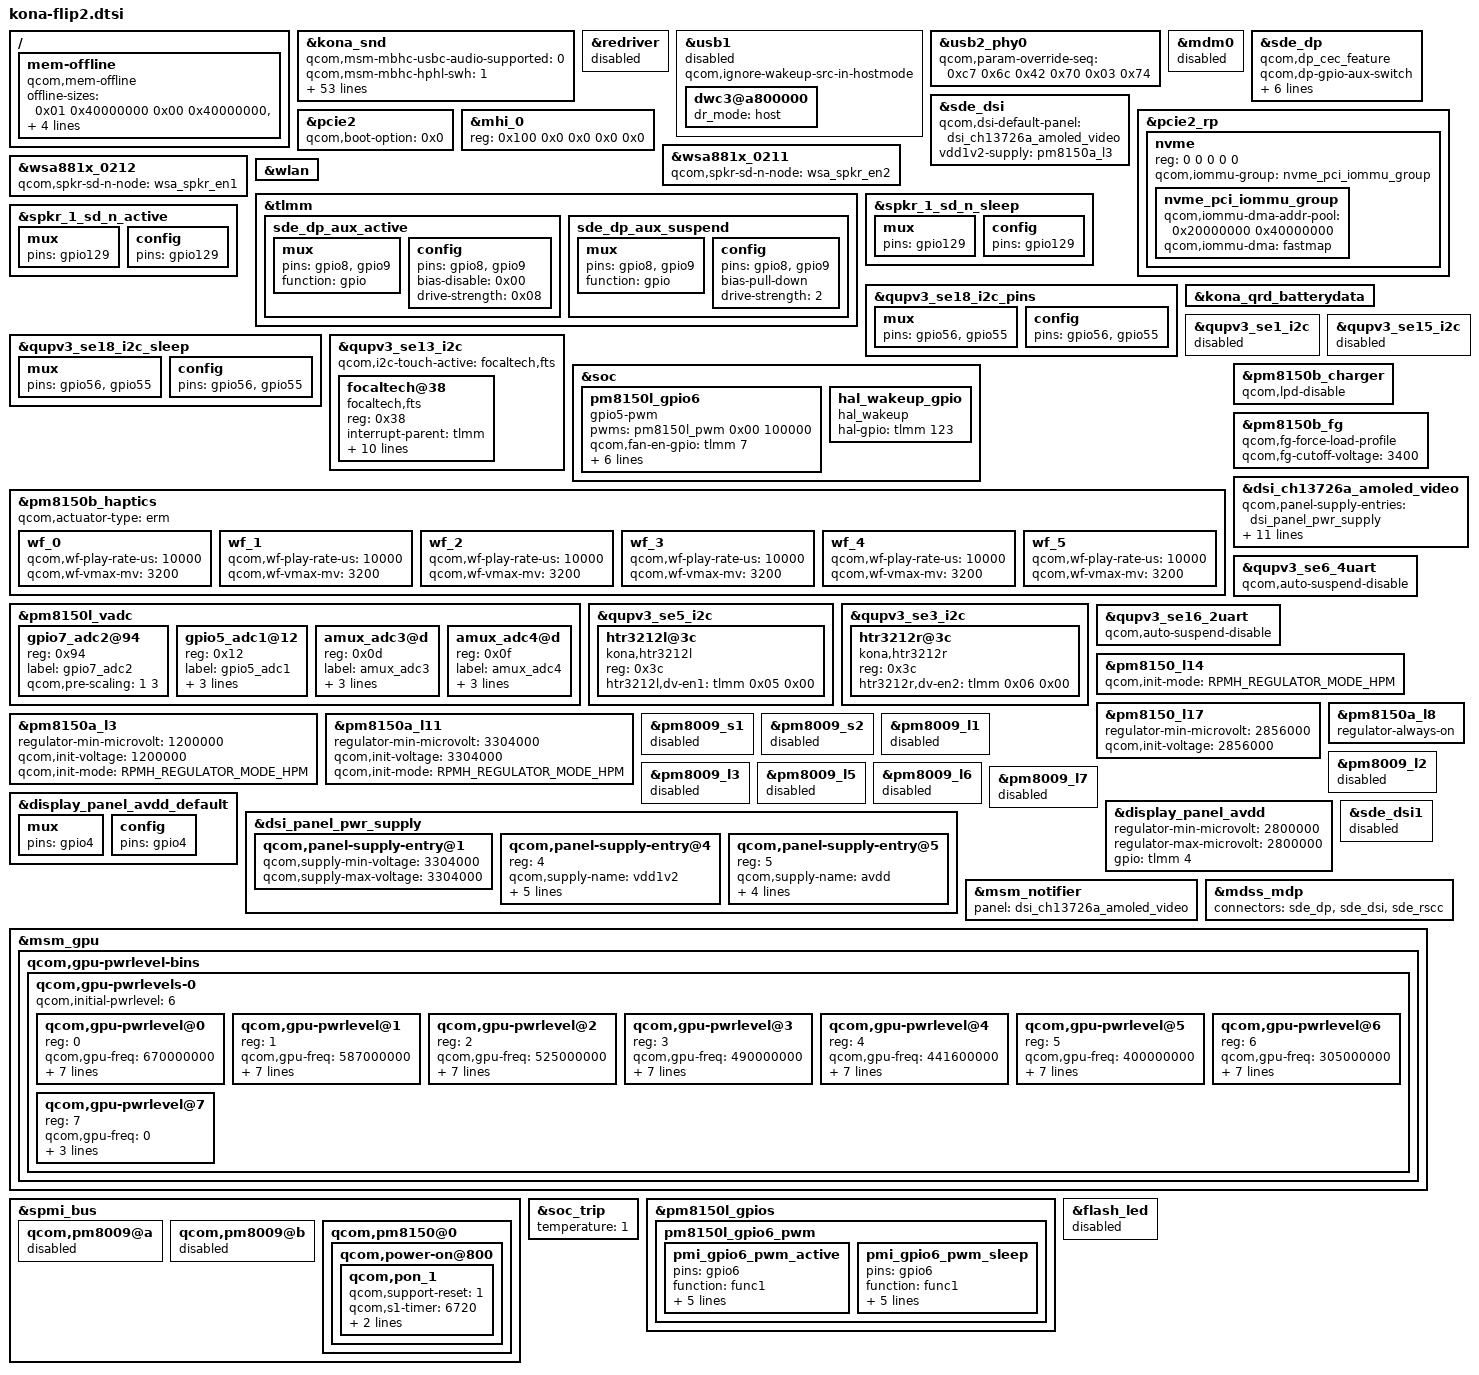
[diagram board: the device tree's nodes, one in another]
#include <dt-bindings/regulator/qcom,rpmh-regulator-levels.h>

#include "../qcom/kona-qrd.dtsi"

&kona_snd {
	qcom,msm-mbhc-usbc-audio-supported = <0>;
	qcom,msm-mbhc-hphl-swh = <1>;
	qcom,msm-mbhc-gnd-swh = <1>;
};

&redriver {
	status = "disabled";
};

&usb1 {
	qcom,ignore-wakeup-src-in-hostmode;

	dwc3@a800000 {
		dr_mode = "host";
	};
};

&usb2_phy0 {
	qcom,param-override-seq =
		<0xc7 0x6c
		0x42 0x70
		0x03 0x74>;
};

&mdm0 {
	status = "disabled";
};

&sde_dp {
	qcom,dp_cec_feature;
};

&sde_dsi {
	qcom,dsi-default-panel = <&dsi_ext_bridge_1080p>;
};

&pcie2 {
	qcom,boot-option = <0x0>;
};

&mhi_0 {
	reg = <0x100 0x0 0x0 0x0 0x0>;
};

&pcie2_rp {
	#address-cells = <5>;
	#size-cells = <0>;

	nvme: nvme {
		reg = <0 0 0 0 0>;
		qcom,iommu-group = <&nvme_pci_iommu_group>;

		#address-cells = <1>;
		#size-cells = <1>;

		nvme_pci_iommu_group: nvme_pci_iommu_group {
			qcom,iommu-dma-addr-pool = <0x20000000 0x40000000>;
			qcom,iommu-dma = "fastmap";
		};
	};
};

&wsa881x_0211 {
	qcom,spkr-sd-n-node = <&wsa_spkr_en2>;
};

&wsa881x_0212 {
	qcom,spkr-sd-n-node = <&wsa_spkr_en1>;
};

&kona_snd {
	/delete-property/ qcom,cdc-dmic01-gpios;
	/delete-property/ qcom,cdc-dmic23-gpios;
	/delete-property/ qcom,cdc-dmic45-gpios;
};

/ {
	mem-offline {
		compatible = "qcom,mem-offline";
		offline-sizes = <0x01 0x40000000 0x00 0x40000000>,
			<0x01 0xc0000000 0x00 0x80000000>,
			<0x02 0xc0000000 0x01 0x40000000>;
		granule = <512>;
		mboxes = <&qmp_aop 0x00>;
	};
};

&mdm0 {
	status = "disabled";
};

&wlan {
	/delete-property/ qcom,sw-ctrl-gpio;
	/delete-property/ vdd-wlan-dig-supply;
	/delete-property/ qcom,vdd-wlan-dig-config;
};

&tlmm {
	sde_dp_aux_active: sde_dp_aux_active {
		mux {
			pins = "gpio8", "gpio9";
			function = "gpio";
		};

		config {
			pins = "gpio8", "gpio9";
			bias-disable = <0x00>;
			drive-strength = <0x08>;
		};
	};

	sde_dp_aux_suspend: sde_dp_aux_suspend {
			mux {
				pins = "gpio8", "gpio9";
				function = "gpio";
			};

			config {
				pins = "gpio8", "gpio9";
				bias-pull-down;         /* PULL DOWN */
				drive-strength = <2>;   /* 2 MA */
			};
	};
};

&spkr_1_sd_n_sleep {
	mux {
		pins = "gpio129";
	};

	config {
		pins = "gpio129";
	};
};

&spkr_1_sd_n_active {
	mux {
		pins = "gpio129";
	};

	config {
		pins = "gpio129";
	};
};

&qupv3_se18_i2c_pins {
	mux {
		pins = "gpio56", "gpio55";
	};

	config {
		pins = "gpio56", "gpio55";
	};
};

&qupv3_se18_i2c_sleep {
	mux {
		pins = "gpio56", "gpio55";
	};

	config {
		pins = "gpio56", "gpio55";
	};
};

&kona_qrd_batterydata {
	#include "fg-gen4-batterydata-7717264-quectel-sg865w-5000mah.dtsi"
};

&kona_snd {
	qcom,audio-routing =
		"AMIC2", "MIC BIAS2",
		"MIC BIAS2", "Analog Mic2",
		"TX DMIC0", "MIC BIAS3",
		"MIC BIAS3", "Digital Mic0",
		"TX DMIC1", "MIC BIAS3",
		"MIC BIAS3", "Digital Mic1",
		"TX DMIC2", "MIC BIAS1",
		"MIC BIAS1", "Digital Mic2",
		"TX DMIC3", "MIC BIAS1",
		"MIC BIAS1", "Digital Mic3",
		"TX DMIC5", "MIC BIAS4",
		"MIC BIAS4", "Digital Mic5",
		"DMIC2", "MIC BIAS3",
		"MIC BIAS3", "Digital Mic2",
		"DMIC3", "MIC BIAS3",
		"MIC BIAS3", "Digital Mic3",
		"DMIC4", "MIC BIAS3",
		"MIC BIAS3", "Digital Mic4",
		"DMIC5", "MIC BIAS3",
		"MIC BIAS3", "Digital Mic5",
		"IN1_HPHL", "HPHL_OUT",
		"IN2_HPHR", "HPHR_OUT",
		"IN3_AUX", "AUX_OUT",
		"TX SWR_ADC0", "ADC1_OUTPUT",
		"TX SWR_ADC1", "ADC2_OUTPUT",
		"TX SWR_ADC2", "ADC3_OUTPUT",
		"TX SWR_ADC3", "ADC4_OUTPUT",
		"TX SWR_DMIC0", "DMIC1_OUTPUT",
		"TX SWR_DMIC1", "DMIC2_OUTPUT",
		"TX SWR_DMIC2", "DMIC3_OUTPUT",
		"TX SWR_DMIC3", "DMIC4_OUTPUT",
		"TX SWR_DMIC4", "DMIC5_OUTPUT",
		"TX SWR_DMIC5", "DMIC6_OUTPUT",
		"TX SWR_DMIC6", "DMIC7_OUTPUT",
		"TX SWR_DMIC7", "DMIC8_OUTPUT",
		"WSA SRC0_INP", "SRC0",
		"WSA_TX DEC0_INP", "TX DEC0 MUX",
		"WSA_TX DEC1_INP", "TX DEC1 MUX",
		"RX_TX DEC0_INP", "TX DEC0 MUX",
		"RX_TX DEC1_INP", "TX DEC1 MUX",
		"RX_TX DEC2_INP", "TX DEC2 MUX",
		"RX_TX DEC3_INP", "TX DEC3 MUX",
 		"SpkrLeft IN", "WSA_SPK1 OUT",
		"SpkrRight IN", "WSA_SPK2 OUT",
		"VA_AIF1 CAP", "VA_SWR_CLK",
		"VA_AIF2 CAP", "VA_SWR_CLK",
		"VA_AIF3 CAP", "VA_SWR_CLK",
		"VA MIC BIAS3", "Digital Mic0",
		"VA MIC BIAS3", "Digital Mic1",
		"VA MIC BIAS1", "Digital Mic2",
		"VA MIC BIAS1", "Digital Mic3",
		"VA MIC BIAS4", "Digital Mic5",
		"VA DMIC0", "VA MIC BIAS3",
		"VA DMIC1", "VA MIC BIAS3",
		"VA DMIC2", "VA MIC BIAS1",
		"VA DMIC3", "VA MIC BIAS1",
		"VA DMIC5", "VA MIC BIAS4",
		"VA SWR_ADC1", "VA_SWR_CLK",
		"VA SWR_MIC0", "VA_SWR_CLK",
		"VA SWR_MIC1", "VA_SWR_CLK",
		"VA SWR_MIC2", "VA_SWR_CLK",
		"VA SWR_MIC3", "VA_SWR_CLK",
		"VA SWR_MIC4", "VA_SWR_CLK",
		"VA SWR_MIC5", "VA_SWR_CLK",
		"VA SWR_MIC6", "VA_SWR_CLK",
		"VA SWR_MIC7", "VA_SWR_CLK",
		"VA SWR_MIC0", "DMIC1_OUTPUT",
		"VA SWR_MIC1", "DMIC2_OUTPUT",
		"VA SWR_MIC2", "DMIC3_OUTPUT",
		"VA SWR_MIC3", "DMIC4_OUTPUT",
		"VA SWR_MIC4", "DMIC5_OUTPUT",
		"VA SWR_MIC5", "DMIC6_OUTPUT",
		"VA SWR_MIC6", "DMIC7_OUTPUT",
		"VA SWR_MIC7", "DMIC8_OUTPUT",
		"VA SWR_ADC1", "ADC2_OUTPUT";
	qcom,wsa-max-devs = <2>;
	qcom,wsa-devs = <&wsa881x_0211>, <&wsa881x_0212>;
	qcom,wsa-aux-dev-prefix = "SpkrLeft", "SpkrRight";
};

&qupv3_se1_i2c {
	status = "disabled";
};

&qupv3_se13_i2c {
	#address-cells = <1>;
	#size-cells = <0>;

	status = "ok";
	qcom,i2c-touch-active = "focaltech,fts";

	focaltech@38 {
		compatible = "focaltech,fts";
		reg = <0x38>;
		interrupt-parent = <&tlmm>;
		interrupts = <39 0x2008>;
		focaltech,reset-gpio = <&tlmm 38 0x00>;
		focaltech,irq-gpio = <&tlmm 39 0x2008>;
		vdd-supply = <&pm8150_l13>;
		vcc_i2c-supply = <&pm8150a_l1>;
		focaltech,max-touch-number = <5>;
		focaltech,display-coords = <0 0 1080 1920>;
		pinctrl-names = "pmx_ts_active", "pmx_ts_suspend";
		pinctrl-0 = <&ts_active>;
		pinctrl-1 = <&ts_int_suspend &ts_reset_suspend>;
		panel = <&dsi_ch13726a_amoled_video>;
	};
};

&soc {
	pm8150l_gpio6 {
		compatible = "gpio5-pwm";
		status = "ok";
		pwms = <&pm8150l_pwm 0x00 100000>;
		qcom,fan-en-gpio = <&tlmm 7 0x00>;
		qcom,fan-fg-gpio = <&tlmm 0 0x2004>;
		gpio5-pwm-state = <1>;
		gpio5-pwm-duty-ns = <10000>;
		gpio5-pwm-period-ns = <50000>;
		pinctrl-names = "default", "fg_int";
		pinctrl-0 = <&pmi_gpio6_pwm_active>;
		pinctrl-1 = <&fg_int_default>;
	};

	hal_wakeup_gpio {
		compatible = "hal_wakeup";
		hal-gpio = <&tlmm 123 0x00>;
	};
};

&pm8150b_haptics {
	wf_0 {
		/* CLICK */
		qcom,wf-play-rate-us = <10000>;
		qcom,wf-vmax-mv = <3200>;
	};

	wf_1 {
		/* DOUBLE CLICK */
		qcom,wf-play-rate-us = <10000>;
		qcom,wf-vmax-mv = <3200>;
	};

	wf_2 {
		/* TICK */
		qcom,wf-play-rate-us = <10000>;
		qcom,wf-vmax-mv = <3200>;
	};

	wf_3 {
		/* THUD */
		qcom,wf-play-rate-us = <10000>;
		qcom,wf-vmax-mv = <3200>;
	};

	wf_4 {
		/* POP */
		qcom,wf-play-rate-us = <10000>;
		qcom,wf-vmax-mv = <3200>;
	};

	wf_5 {
		/* HEAVY CLICK */
		qcom,wf-play-rate-us = <10000>;
		qcom,wf-vmax-mv = <3200>;
	};
};

&qupv3_se15_i2c {
	status = "disabled";
};

&pm8150b_charger {
	qcom,lpd-disable;
};

&pm8150b_fg {
	qcom,fg-force-load-profile;
	qcom,fg-cutoff-voltage = <3400>;
};

&pm8150l_vadc {

	gpio7_adc2@94 {
		reg = <0x94>;
		label = "gpio7_adc2";
		qcom,pre-scaling = <1 3>;
	};

	gpio5_adc1@12 {
		reg = <0x12>;
		label = "gpio5_adc1";
		qcom,ratiometric;
		qcom,hw-settle-time = <200>;
		qcom,pre-scaling = <1 1>;
	};

	amux_adc3@d {
		reg = <0x0d>;
		label = "amux_adc3";
		qcom,ratiometric;
		qcom,hw-settle-time = <200>;
		qcom,pre-scaling = <1 1>;
	};

	amux_adc4@d {
		reg = <0x0f>;
		label = "amux_adc4";
		qcom,ratiometric;
		qcom,hw-settle-time = <200>;
		qcom,pre-scaling = <1 1>;
	};
};

&qupv3_se5_i2c {
	#address-cells = <0x01>;
	#size-cells = <0x00>;
	status = "ok";

	htr3212l@3c {
		compatible = "kona,htr3212l";
		reg = <0x3c>;
		htr3212l,dv-en1 = <&tlmm 0x05 0x00>;
	};
};

&qupv3_se3_i2c {
	#address-cells = <0x01>;
	#size-cells = <0x00>;
	status = "ok";

	htr3212r@3c {
		compatible = "kona,htr3212r";
		reg = <0x3c>;
		htr3212r,dv-en2 = <&tlmm 0x06 0x00>;
	};
};

&dsi_ch13726a_amoled_video {
	qcom,panel-supply-entries = <&dsi_panel_pwr_supply>;
	qcom,mdss-dsi-bl-pmic-control-type = "bl_ctrl_dcs";
	qcom,mdss-dsi-bl-min-level = <1>;
	qcom,mdss-dsi-bl-max-level = <255>;
	qcom,mdss-brightness-max-level = <255>;
	qcom,platform-te-gpio = <&tlmm 66 0>;
	qcom,platform-reset-gpio = <&tlmm 75 0>;
	qcom,platform-mipi-mode-sel = <&tlmm 10 0>;
	qcom,platform-mipi-mode-oe = <&tlmm 11 0>;
	qcom,platform-mipi-vdd = <&tlmm 28 0>;
	qcom,mdss-dsi-panel-test-pin = <&tlmm 46 0>;
};

&qupv3_se6_4uart {
	qcom,auto-suspend-disable;
};

// joystick
&qupv3_se16_2uart {
	status = "ok";
	qcom,auto-suspend-disable;
};

// display vddio
&pm8150_l14 {
	qcom,init-mode = <RPMH_REGULATOR_MODE_HPM>;
};

// ufs vcc
&pm8150_l17 {
	regulator-min-microvolt = <2856000>;
	qcom,init-voltage = <2856000>;
};

// display vdd1v2
&pm8150a_l3 {
	regulator-min-microvolt = <1200000>;
	qcom,init-voltage = <1200000>;
	qcom,init-mode = <RPMH_REGULATOR_MODE_HPM>;
};

// ???
&pm8150a_l8 {
	regulator-always-on;
};

// display vdd
&pm8150a_l11 {
	regulator-min-microvolt = <3304000>;
	qcom,init-voltage = <3304000>;
	qcom,init-mode = <RPMH_REGULATOR_MODE_HPM>;
};

&pm8009_s1 {
	status = "disabled";
};

&pm8009_s2 {
	status = "disabled";
};

&pm8009_l1 {
	status = "disabled";
};

&pm8009_l2 {
	status = "disabled";
};

&pm8009_l3 {
	status = "disabled";
};

&pm8009_l5 {
	status = "disabled";
};

&pm8009_l6 {
	status = "disabled";
};

&pm8009_l7 {
	status = "disabled";
};

&display_panel_avdd_default {
	mux {
		pins = "gpio4";
	};

	config {
		pins = "gpio4";
	};
};

&dsi_panel_pwr_supply {
	qcom,panel-supply-entry@1 {
		qcom,supply-min-voltage = <3304000>;
		qcom,supply-max-voltage = <3304000>;
	};

	qcom,panel-supply-entry@4 {
		reg = <4>;
		qcom,supply-name = "vdd1v2";
		qcom,supply-min-voltage = <1200000>;
		qcom,supply-max-voltage = <1200000>;
		qcom,supply-enable-load = <100000>;
		qcom,supply-disable-load = <100>;
		qcom,supply-post-on-sleep = <20>;
	};

	qcom,panel-supply-entry@5 {
		reg = <5>;
		qcom,supply-name = "avdd";
		qcom,supply-min-voltage = <2800000>;
		qcom,supply-max-voltage = <2800000>;
		qcom,supply-enable-load = <100000>;
		qcom,supply-disable-load = <10>;
	};
};

&display_panel_avdd {
	regulator-min-microvolt = <2800000>;
	regulator-max-microvolt = <2800000>;
	gpio = <&tlmm 4 0>;
};

&sde_dsi {
	vdd1v2-supply = <&pm8150a_l3>;
	/delete-property/ lab-supply;
	/delete-property/ ibb-supply;
	qcom,dsi-default-panel = <&dsi_ch13726a_amoled_video>;
};

&sde_dsi1 {
	status = "disabled";
};

&msm_notifier {
	panel = <&dsi_ch13726a_amoled_video>;
};

&sde_dp {
	/delete-property/ qcom,dp-aux-switch;
	qcom,dp-gpio-aux-switch;
	qcom,aux-en-gpio = <&tlmm 9 0>;
	qcom,aux-sel-gpio = <&tlmm 8 0>;
	pinctrl-0 = <&sde_dp_aux_active &sde_dp_usbplug_cc_active>;
	pinctrl-1 = <&sde_dp_aux_suspend &sde_dp_usbplug_cc_suspend>;
};

&mdss_mdp {
	connectors = <&sde_dp &sde_dsi &sde_rscc>;
};

&usb1 {
	status = "disabled";
};

&msm_gpu {
	qcom,gpu-pwrlevel-bins {
		qcom,gpu-pwrlevels-0 {
			qcom,initial-pwrlevel = <6>;

			qcom,gpu-pwrlevel@0 {
				reg = <0>;
				qcom,gpu-freq = <670000000>;
				qcom,bus-freq-ddr7 = <11>;
				qcom,bus-min-ddr7 = <11>;
				qcom,bus-max-ddr7 = <11>;

				qcom,bus-freq-ddr8 = <11>;
				qcom,bus-min-ddr8 = <11>;
				qcom,bus-max-ddr8 = <11>;

				qcom,acd-level = <0x802b5ffd>;
			};

			qcom,gpu-pwrlevel@1 {
				reg = <1>;
				qcom,gpu-freq = <587000000>;
				qcom,bus-freq-ddr7 = <11>;
				qcom,bus-min-ddr7 = <11>;
				qcom,bus-max-ddr7 = <11>;

				qcom,bus-freq-ddr8 = <11>;
				qcom,bus-min-ddr8 = <11>;
				qcom,bus-max-ddr8 = <11>;

				qcom,acd-level = <0x802b5ffd>;
			};

			qcom,gpu-pwrlevel@2 {
				reg = <2>;
				qcom,gpu-freq = <525000000>;
				qcom,bus-freq-ddr7 = <9>;
				qcom,bus-min-ddr7 = <9>;
				qcom,bus-max-ddr7 = <11>;

				qcom,bus-freq-ddr8 = <8>;
				qcom,bus-min-ddr8 = <8>;
				qcom,bus-max-ddr8 = <11>;

				qcom,acd-level = <0x802b5ffd>;
			};

			qcom,gpu-pwrlevel@3 {
				reg = <3>;
				qcom,gpu-freq = <490000000>;
				qcom,bus-freq-ddr7 = <9>;
				qcom,bus-min-ddr7 = <6>;
				qcom,bus-max-ddr7 = <9>;

				qcom,bus-freq-ddr8 = <8>;
				qcom,bus-min-ddr8 = <7>;
				qcom,bus-max-ddr8 = <9>;

				qcom,acd-level = <0xa02b5ffd>;
			};

			qcom,gpu-pwrlevel@4 {
				reg = <4>;
				qcom,gpu-freq = <441600000>;
				qcom,bus-freq-ddr7 = <9>;
				qcom,bus-min-ddr7 = <6>;
				qcom,bus-max-ddr7 = <9>;

				qcom,bus-freq-ddr8 = <8>;
				qcom,bus-min-ddr8 = <7>;
				qcom,bus-max-ddr8 = <9>;

				qcom,acd-level = <0xa02b5ffd>;
			};

			qcom,gpu-pwrlevel@5 {
				reg = <5>;
				qcom,gpu-freq = <400000000>;
				qcom,bus-freq-ddr7 = <7>;
				qcom,bus-min-ddr7 = <6>;
				qcom,bus-max-ddr7 = <9>;

				qcom,bus-freq-ddr8 = <8>;
				qcom,bus-min-ddr8 = <6>;
				qcom,bus-max-ddr8 = <9>;

				qcom,acd-level = <0xa02b5ffd>;
			};

			qcom,gpu-pwrlevel@6 {
				reg = <6>;
				qcom,gpu-freq = <305000000>;
				qcom,bus-freq-ddr7 = <3>;
				qcom,bus-min-ddr7 = <2>;
				qcom,bus-max-ddr7 = <9>;

				qcom,bus-freq-ddr8 = <3>;
				qcom,bus-min-ddr8 = <2>;
				qcom,bus-max-ddr8 = <9>;

				qcom,acd-level = <0xa02b5ffd>;
			};

			qcom,gpu-pwrlevel@7 {
				reg = <7>;
				qcom,gpu-freq = <0>;
				qcom,bus-freq = <0>;
				qcom,bus-min = <0>;
				qcom,bus-max = <0>;
			};
		};
	};
};

&spmi_bus {
	qcom,pm8009@a {
		status = "disabled";
	};

	qcom,pm8009@b {
		status = "disabled";
	};
};

&pm8150b_haptics {
	qcom,actuator-type = "erm";
};

&soc_trip {
	temperature = <1>;
};

&spmi_bus {
	qcom,pm8150@0 {
		qcom,power-on@800 {
			qcom,pon_1 {
				qcom,support-reset = <1>;
				qcom,s1-timer = <6720>;
				qcom,s2-timer = <2000>;
				qcom,s2-type = <4>;
			};
		};
	};
};

&pm8150l_gpios {
	pm8150l_gpio6_pwm {
		pmi_gpio6_pwm_active: pmi_gpio6_pwm_active {
			pins = "gpio6";
			function = "func1";
			bias-disable;
			power-source = <0x00>;
			output-low;
			qcom,drive-strength = <0x03>;
			drive-push-pull;
		};

		pmi_gpio6_pwm_sleep: pmi_gpio6_pwm_sleep {
			pins = "gpio6";
			function = "func1";
			bias-disable;
			power-source = <0x00>;
			output-low;
			qcom,drive-strength = <0x03>;
			drive-push-pull;
		};
	};
};

&flash_led {
	status = "disable";
};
